VERSION ""

NS_ :

BS_:

BU_: Charger BMS Hub

BO_ 2364577523 SAE_HVESSS1: 8 BMS

BO_ 2633785075 SAE_HVESSHIST: 37 BMS
 SG_ SoH : 0|8@1+ (0.4,0) [0|100] "%" Vector__XXX

BO_ 2566675955 SAE_HVESSCFG: 17 BMS

BO_ 2364580083 SAE_HVESSD7: 8 BMS
 SG_ ChargeEnergyCapacity : 24|24@1+ (0.001,0) [0|16449.535] "kWh" Vector__XXX
 SG_ DischargeEnergyCapacity : 0|24@1+ (0.001,0) [0|16449.535] "kWh" Vector__XXX

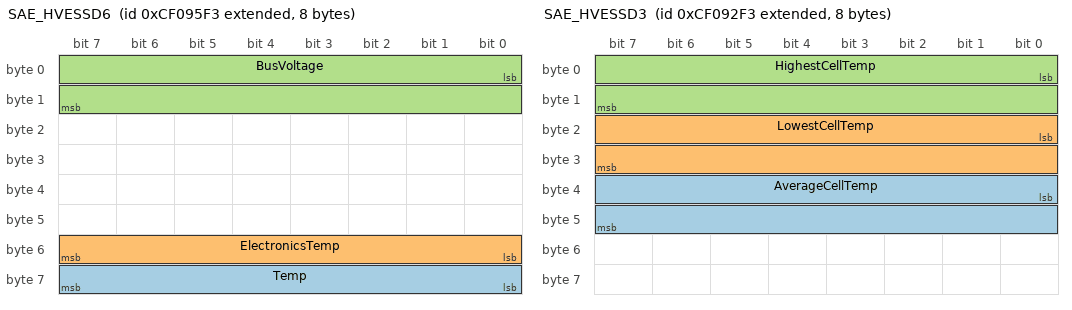
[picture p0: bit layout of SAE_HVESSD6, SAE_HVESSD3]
BO_ 2364577267 SAE_HVESSD6: 8 BMS
 SG_ Temp : 56|8@1+ (1,-40) [-40|210] "C" Vector__XXX
 SG_ ElectronicsTemp : 48|8@1+ (1,-40) [-40|210] "C" Vector__XXX
 SG_ BusVoltage : 0|16@1+ (0.05,0) [0|3212.75] "V" Vector__XXX

BO_ 2364577011 SAE_HVESSD5: 7 BMS
 SG_ ChargeCurrentLimit : 16|16@1+ (0.05,-1600) [-1600|1612.75] "A" Vector__XXX
 SG_ DischargeCurrentLimit : 0|16@1+ (0.05,-1600) [-1600|1612.75] "A" Vector__XXX

BO_ 2364576755 SAE_HVESSD4: 8 BMS
 SG_ ChargeCapacity : 16|16@1+ (0.01,0) [0|642.55] "Ah" Vector__XXX
 SG_ DischargeCapacity : 0|16@1+ (0.01,0) [0|642.55] "Ah" Vector__XXX

BO_ 2364576499 SAE_HVESSD3: 8 BMS
 SG_ AverageCellTemp : 32|16@1+ (0.03125,-273) [-273|1734.96875] "C" Vector__XXX
 SG_ LowestCellTemp : 16|16@1+ (0.03125,-273) [-273|1734.96875] "C" Vector__XXX
 SG_ HighestCellTemp : 0|16@1+ (0.03125,-273) [-273|1734.96875] "C" Vector__XXX

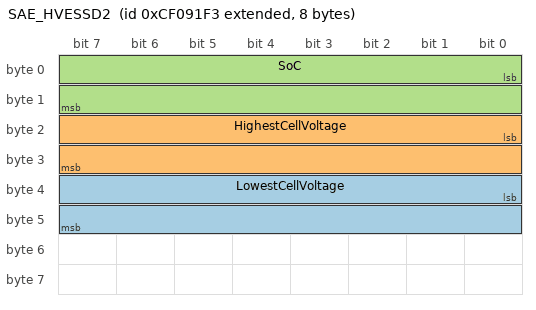
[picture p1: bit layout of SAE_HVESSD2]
BO_ 2364576243 SAE_HVESSD2: 8 BMS
 SG_ LowestCellVoltage : 32|16@1+ (0.001,0) [0|64.255] "V" Vector__XXX
 SG_ HighestCellVoltage : 16|16@1+ (0.001,0) [0|64.255] "V" Vector__XXX
 SG_ SoC : 0|16@1+ (0.0015625,0) [0|100.3984375] "%" Vector__XXX

BO_ 2364575987 SAE_HVESSD1: 8 BMS
 SG_ Current : 48|16@1+ (0.05,-1600) [-1600|1612.75] "A" Vector__XXX
 SG_ VoltageLevel : 32|16@1+ (0.05,0) [0|3212.75] "V" Vector__XXX

BO_ 2566722889 SAE_BCH1: 8 Charger
 SG_ BatteryCharger1OutputCurrent : 24|16@1+ (0.05,-1600) [-1600|1612.75] "A" Vector__XXX
 SG_ BatteryCharger1OutputVoltage : 8|16@1+ (0.05,0) [0|3212.75] "V" Vector__XXX

BO_ 2350642096 SAE_HVESSC1: 8 Hub

CM_ BO_ 2364577523 "Status data set 1 for High Voltage Energy Storage System (or Pack 1 in systems with only one pack).";
CM_ BO_ 2633785075 "Historical data for High Voltage Energy Storage System (or Pack 1 in systems with only one pack).";
CM_ BO_ 2566675955 "Configuration data for High Voltage Energy Storage System (or Pack 1 in systems with only one pack).
Note that configuration data should not dynamically change during vehicle operation.";
CM_ BO_ 2364580083 "Data set 7 (electrical) for High Voltage Energy Storage System (or Pack 1 in systems with only one pack).";
CM_ BO_ 2364577267 "Data set 6 (external or interface data) for High Voltage Energy Storage System (or Pack 1 in systems with only one pack).";
CM_ BO_ 2364577011 "Data set 5 (electrical data) for High Voltage Energy Storage System (or Pack 1 in systems with only one pack).";
CM_ BO_ 2364576755 "Data set 4 (electrical data) for High Voltage Energy Storage System (or Pack 1 in systems with only one pack).";
CM_ BO_ 2364576499 "Data set 3 (thermal data) for High Voltage Energy Storage System (or Pack 1 in systems with only one pack).";
CM_ BO_ 2364576243 "Data set 2 (electrical data) for High Voltage Energy Storage System (or Pack 1 in systems with only one pack).";
CM_ BO_ 2364575987 "Data set 1 (electrical data) for High Voltage Energy Storage System (or Pack 1 in systems with only one pack).";
CM_ BO_ 2566722889 "Parameters for the battery charger connected to the main battery.";
CM_ BO_ 2350642096 "Control commands to be sent to High Voltage Energy Storage System (or Pack 1 in systems with only one pack).";
BA_DEF_ SG_  "SigType" ENUM  "Default","Range","RangeSigned","ASCII","Discrete","Control","ReferencePGN","DTC","StringDelimiter","StringLength","StringLengthControl","MessageCounter","MessageChecksum";
BA_DEF_ SG_  "GenSigEVName" STRING ;
BA_DEF_ SG_  "GenSigILSupport" ENUM  "No","Yes";
BA_DEF_ SG_  "GenSigSendType" ENUM  "Cyclic","OnWrite","OnWriteWithRepetition","OnChange","OnChangeWithRepetition","IfActive","IfActiveWithRepetition","NoSigSendType";
BA_DEF_ SG_  "GenSigStartValue" INT 0 2147483647;
BA_DEF_ BO_  "GenMsgILSupport" ENUM  "No","Yes";
BA_DEF_ BU_  "NmStationAddress" INT 0 255;
BA_DEF_ BO_  "GenMsgSendType" ENUM  "cyclic","NotUsed","IfActive","NotUsed","NotUsed","NotUsed","NotUsed","NotUsed","noMsgSendType";
BA_DEF_ BO_  "GenMsgRequestable" INT 0 1;
BA_DEF_ BO_  "GenMsgCycleTime" INT 0 3600000;
BA_DEF_ SG_  "SPN" INT 0 524287;
BA_DEF_  "DBName" STRING ;
BA_DEF_  "BusType" STRING ;
BA_DEF_  "ProtocolType" STRING ;
BA_DEF_DEF_  "SigType" "Default";
BA_DEF_DEF_  "GenSigEVName" "Env@Nodename_@Signame";
BA_DEF_DEF_  "GenSigILSupport" "Yes";
BA_DEF_DEF_  "GenSigSendType" "NoSigSendType";
BA_DEF_DEF_  "GenSigStartValue" 0;
BA_DEF_DEF_  "GenMsgILSupport" "Yes";
BA_DEF_DEF_  "NmStationAddress" 254;
BA_DEF_DEF_  "GenMsgSendType" "noMsgSendType";
BA_DEF_DEF_  "GenMsgRequestable" 1;
BA_DEF_DEF_  "GenMsgCycleTime" 0;
BA_DEF_DEF_  "SPN" 0;
BA_DEF_DEF_  "DBName" "";
BA_DEF_DEF_  "BusType" "CAN";
BA_DEF_DEF_  "ProtocolType" "J1939";
BA_DEF_DEF_  "VFrameFormat" "J1939PG";
BA_ "DBName" "CAN_E";
BA_ "NmStationAddress" BU_ Charger 73;
BA_ "NmStationAddress" BU_ BMS 243;
BA_ "NmStationAddress" BU_ Hub 176;
BA_ "GenMsgCycleTime" BO_ 2364577523 100;
BA_ "VFrameFormat" BO_ 2364577523 3;
BA_ "VFrameFormat" BO_ 2633785075 3;
BA_ "VFrameFormat" BO_ 2566675955 3;
BA_ "GenMsgCycleTime" BO_ 2364580083 100;
BA_ "VFrameFormat" BO_ 2364580083 3;
BA_ "GenMsgCycleTime" BO_ 2364577267 100;
BA_ "VFrameFormat" BO_ 2364577267 3;
BA_ "GenMsgCycleTime" BO_ 2364577011 20;
BA_ "VFrameFormat" BO_ 2364577011 3;
BA_ "GenMsgCycleTime" BO_ 2364576755 100;
BA_ "VFrameFormat" BO_ 2364576755 3;
BA_ "GenMsgCycleTime" BO_ 2364576499 20;
BA_ "VFrameFormat" BO_ 2364576499 3;
BA_ "GenMsgCycleTime" BO_ 2364576243 20;
BA_ "VFrameFormat" BO_ 2364576243 3;
BA_ "GenMsgCycleTime" BO_ 2364575987 20;
BA_ "VFrameFormat" BO_ 2364575987 3;
BA_ "GenMsgCycleTime" BO_ 2566722889 1000;
BA_ "VFrameFormat" BO_ 2566722889 3;
BA_ "GenMsgCycleTime" BO_ 2350642096 20;
BA_ "VFrameFormat" BO_ 2350642096 3;
BA_ "SPN" SG_ 2633785075 SoH 8121;
BA_ "SPN" SG_ 2364580083 ChargeEnergyCapacity 8206;
BA_ "SPN" SG_ 2364580083 DischargeEnergyCapacity 8205;
BA_ "GenSigStartValue" SG_ 2364577267 Temp 40;
BA_ "SPN" SG_ 2364577267 Temp 9119;
BA_ "GenSigStartValue" SG_ 2364577267 ElectronicsTemp 40;
BA_ "SPN" SG_ 2364577267 ElectronicsTemp 8204;
BA_ "SPN" SG_ 2364577267 BusVoltage 8086;
BA_ "GenSigStartValue" SG_ 2364577011 ChargeCurrentLimit 32000;
BA_ "SPN" SG_ 2364577011 ChargeCurrentLimit 8083;
BA_ "GenSigStartValue" SG_ 2364577011 DischargeCurrentLimit 32000;
BA_ "SPN" SG_ 2364577011 DischargeCurrentLimit 8082;
BA_ "SPN" SG_ 2364576755 ChargeCapacity 8080;
BA_ "SPN" SG_ 2364576755 DischargeCapacity 8079;
BA_ "GenSigStartValue" SG_ 2364576499 AverageCellTemp 8736;
BA_ "SPN" SG_ 2364576499 AverageCellTemp 8077;
BA_ "GenSigStartValue" SG_ 2364576499 LowestCellTemp 8736;
BA_ "SPN" SG_ 2364576499 LowestCellTemp 8076;
BA_ "GenSigStartValue" SG_ 2364576499 HighestCellTemp 8736;
BA_ "SPN" SG_ 2364576499 HighestCellTemp 8075;
BA_ "SPN" SG_ 2364576243 LowestCellVoltage 5923;
BA_ "SPN" SG_ 2364576243 HighestCellVoltage 5922;
BA_ "SPN" SG_ 2364576243 SoC 5921;
BA_ "GenSigStartValue" SG_ 2364575987 Current 32000;
BA_ "SPN" SG_ 2364575987 Current 5920;
BA_ "SPN" SG_ 2364575987 VoltageLevel 5919;
BA_ "GenSigStartValue" SG_ 2566722889 BatteryCharger1OutputCurrent 32000;
